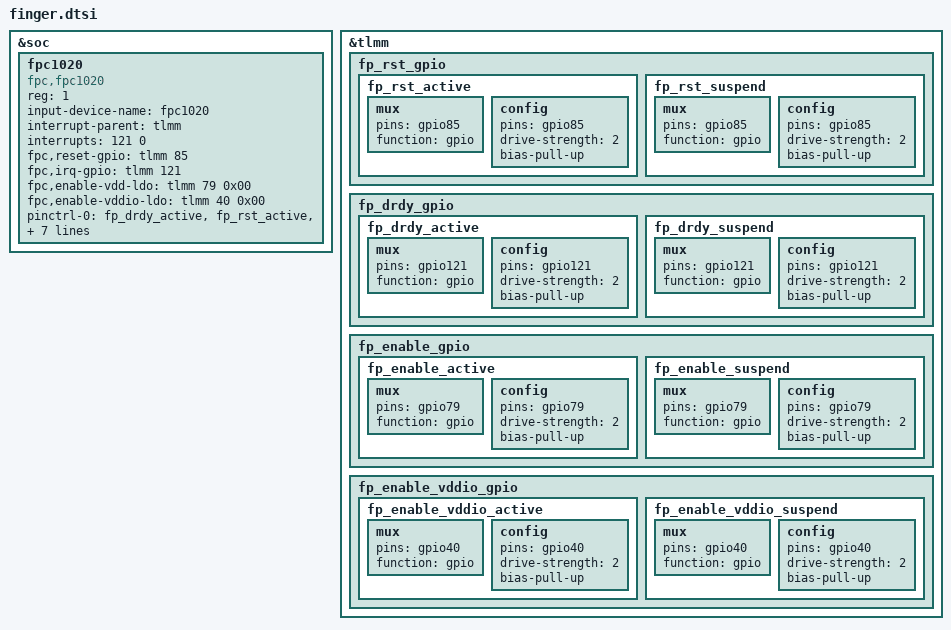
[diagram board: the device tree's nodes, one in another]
/*
 * nubia NX609J finger dts
 */
&soc {
	fpc1020{
		status = "ok";
		reg = <1>;
		compatible = "fpc,fpc1020";
		input-device-name = "fpc1020";
		interrupt-parent = <&tlmm>;
		interrupts = <121 0>;
		fpc,reset-gpio = <&tlmm 85 0x00>;
		fpc,irq-gpio = <&tlmm 121 0x00>;
		fpc,enable-vdd-ldo = <&tlmm 79 0x00>;
		fpc,enable-vddio-ldo = <&tlmm 40 0x00>;
		pinctrl-names = "pmx_fp_active", "pmx_fp_suspend";
		pinctrl-0 = <&fp_drdy_active &fp_rst_active &fp_enable_active &fp_enable_vddio_active>;
		pinctrl-1 = <&fp_drdy_suspend &fp_rst_suspend &fp_enable_suspend &fp_enable_vddio_suspend>;
		spi-max-frequency = <4800000>;
		spi-qup-id = <1>;
		clock-names = "iface_clk", "core_clk";
		clocks = <&clock_gcc clk_gcc_blsp2_ahb_clk>,
			     <&clock_gcc clk_gcc_blsp2_qup6_spi_apps_clk>;
	};
	
	/delete-node/ qcom,qbt1000;
};

&tlmm {
	fp_rst_gpio {
			fp_rst_active: fp_rst_active {
				mux {
					pins = "gpio85";
					function = "gpio";
				};

				config {
					pins = "gpio85";
					drive-strength = <2>;
					bias-pull-up;
				};
			};

			fp_rst_suspend: fp_rst_suspend {
				mux {
					pins = "gpio85";
					function = "gpio";
				};

				config {
					pins = "gpio85";
					drive-strength = <2>;
					bias-pull-up;
				};
			};
		};

		fp_drdy_gpio {
			fp_drdy_active: fp_drdy_active {
				mux {
					pins = "gpio121";
					function = "gpio";
				};

				config {
					pins = "gpio121";
					drive-strength = <2>;
					bias-pull-up;
				};
			};

			fp_drdy_suspend: fp_drdy_suspend {
				mux {
					pins = "gpio121";
					function = "gpio";
				};

				config {
					pins = "gpio121";
					drive-strength = <2>;
					bias-pull-up;
				};
			};
		};

		fp_enable_gpio {
			fp_enable_active: fp_enable_active {
				mux {
					pins = "gpio79";
					function = "gpio";
				};

				config {
					pins = "gpio79";
					drive-strength = <2>;
					bias-pull-up;
				};
			};

			fp_enable_suspend: fp_enable_suspend {
				mux {
					pins = "gpio79";
					function = "gpio";
				};

				config {
					pins = "gpio79";
					drive-strength = <2>;
					bias-pull-up;
				};
			};
		};
		fp_enable_vddio_gpio {
			fp_enable_vddio_active: fp_enable_vddio_active {
				mux {
					pins = "gpio40";
					function = "gpio";
				};

				config {
					pins = "gpio40";
					drive-strength = <2>;
					bias-pull-up;
				};
			};

			fp_enable_vddio_suspend: fp_enable_vddio_suspend {
				mux {
					pins = "gpio40";
					function = "gpio";
				};

				config {
					pins = "gpio40";
					drive-strength = <2>;
					bias-pull-up;
				};
			};
		};
};


